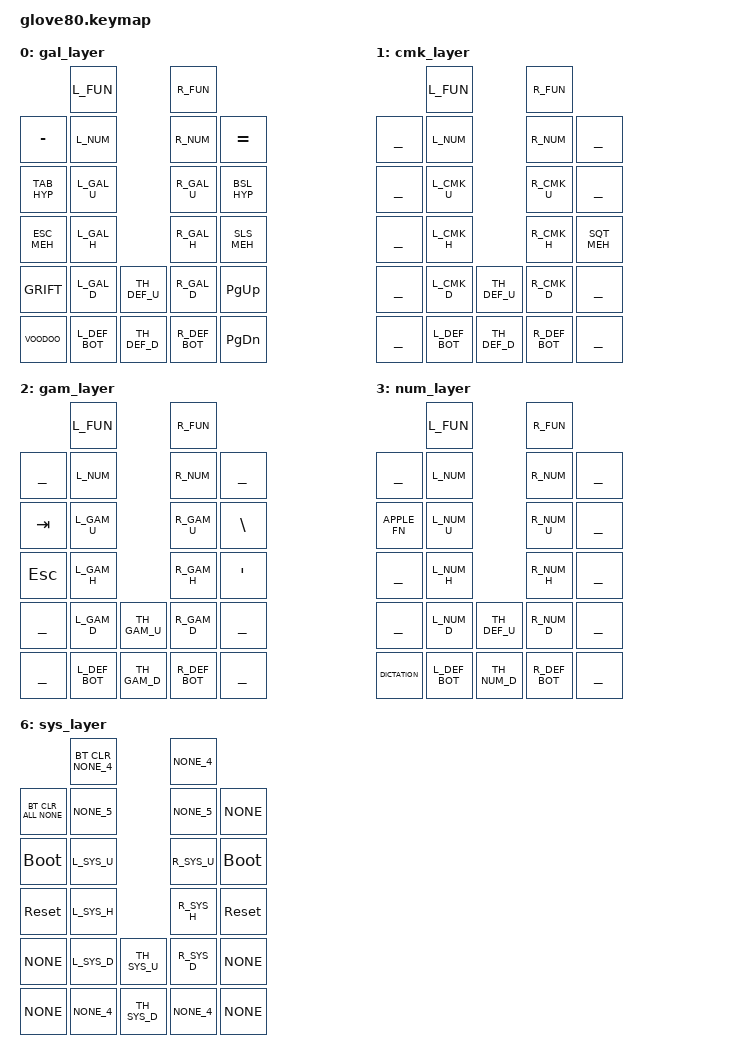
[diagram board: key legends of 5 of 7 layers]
#include <behaviors.dtsi>
#include <dt-bindings/zmk/keys.h>
#include <dt-bindings/zmk/bt.h>
#include <dt-bindings/zmk/ext_power.h>
#include <dt-bindings/zmk/outputs.h>
#include <dt-bindings/zmk/rgb.h>
#include <dt-bindings/zmk/mouse.h>

#include "../zmk-nodefree-config/helper.h"
#include "../zmk-nodefree-config/keypos_def/keypos_glv80.h"

#include "defines.h"
#include "keypos_groups_glv80.h"
#include "custom_behaviors.dtsi"
#include "behaviors_glv80.dtsi"
#include "key_codes.h"
#include "mouse.dtsi"
#include "key_clusters.h"
#include "combos.dtsi"

/* 👍 Thumb Clusters */

// Default 
//               LEFT                          <|>                 RIGHT
#define TH_DEF_U ___      ___        ___         ___      ___      PTR_ENT 
#define TH_DEF_D SPC_NUM  CMD_TAB    OPT_ESC     PTR_ENT  NAV_KEY  SFT_BSP 

#define TH_GAM_U &kp LSHFT &kp DEL   &kp LGUI    ___       ___     ___ 
#define TH_GAM_D &kp SPC   &kp LCTRL &kp LALT    PTR_ENT  NAV_KEY  SFT_BSP 

#define TH_SYS_U &bt_2     &bt_3     ___           NONE_3
#define TH_SYS_D &bt_0     &bt_1     &out OUT_USB  NONE_3

#define TH_NUM_D ___       ___       ___         NONE     &kp DOT  ___ 
#define TH_NAV_D &kp SPACE &kp TAB   &kp ESC     NONE     ___      DICTATION
#define TH_PTR_D &kp SPACE &kp TAB   &kp ESC     U_MS_B3  U_MS_B1  U_MS_B2 

ZMK_LAYER(gal_layer, 
               L_FUN              R_FUN
    &kp MINUS  L_NUM              R_NUM      &kp EQUAL
    TAB_HYP    L_GAL_U            R_GAL_U    BSL_HYP
    ESC_MEH    L_GAL_H            R_GAL_H    SLS_MEH
    GRIFT      L_GAL_D   TH_DEF_U R_GAL_D    &kp PG_UP
    VOODOO     L_DEF_BOT TH_DEF_D R_DEF_BOT  &kp PG_DN    
)

ZMK_LAYER(cmk_layer, 
               L_FUN              R_FUN
    ___        L_NUM              R_NUM      ___
    ___        L_CMK_U            R_CMK_U    ___
    ___        L_CMK_H            R_CMK_H    SQT_MEH
    ___        L_CMK_D   TH_DEF_U R_CMK_D    ___
    ___        L_DEF_BOT TH_DEF_D R_DEF_BOT  ___
)

ZMK_LAYER(gam_layer, 
               L_FUN              R_FUN
    ___        L_NUM              R_NUM      ___
    &kp TAB    L_GAM_U            R_GAM_U    &kp BACKSLASH
    &kp ESC    L_GAM_H            R_GAM_H    &kp SQT
    ___        L_GAM_D   TH_GAM_U R_GAM_D    ___
    ___        L_DEF_BOT TH_GAM_D R_DEF_BOT  ___
)

ZMK_LAYER(num_layer, 
              L_FUN              R_FUN
    ___       L_NUM              R_NUM      ___
    APPLE_FN  L_NUM_U            R_NUM_U    ___
    ___       L_NUM_H            R_NUM_H    ___
    ___       L_NUM_D   TH_DEF_U R_NUM_D    ___
    DICTATION L_DEF_BOT TH_NUM_D R_DEF_BOT  ___
)

ZMK_LAYER(nav_layer, 
    &kp F11 &kp F12  TRAN_3 TRAN_3   &kp C_BRI_DN &kp C_BRI_UP
    ___  L_NUM              R_NUM      ___
    ___  L_NAV_U            R_NAV_U    ___
    ___  L_NAV_H            R_NAV_H    ___
    ___  L_NAV_D   TH_DEF_U R_NAV_D    ___
    ___  L_DEF_BOT TH_NAV_D R_DEF_BOT  ___   
)

ZMK_LAYER(ptr_layer, 
                           // CHANGE BASE KEYMAP LAYER on F6-F10
         L_FUN        TO_GAL TO_CMK TO_GAM EXIT EXIT
    ___  L_NUM              R_NUM      ___
    ___  L_PTR_U            R_PTR_U    ___
    ___  L_PTR_H            R_PTR_H    ___
    ___  L_PTR_D   TH_DEF_U R_PTR_D    ___
    ___  L_DEF_BOT TH_PTR_D R_DEF_BOT  ___
)

ZMK_LAYER(sys_layer, 
    &bt BT_CLR  NONE_4             NONE_4 &bt BT_CLR_ALL
    NONE        NONE_5             NONE_5 NONE
    &bootloader L_SYS_U           R_SYS_U &bootloader
    &sys_reset  L_SYS_H           R_SYS_H &sys_reset
    NONE        L_SYS_D  TH_SYS_U R_SYS_D NONE
    NONE        NONE_4   TH_SYS_D NONE_4  NONE
)

// ZMK_LAYER(rec_layer, 
//          L_FUN                 R_FUN
//     ___  L_NUM                 R_NUM    ___
//     ___  L_REC_U               R_REC_U  ___
//     ___  L_REC_H               R_REC_H  ___
//     ___  L_REC_D TRAN_3 TRAN_3 R_REC_D  ___
//     ___  TRAN_4  TRAN_3 TRAN_3 TRAN_4   ___
// )

// ZMK_LAYER(fun_layer, 
//          L_FUN                 R_FUN
//     ___  L_FUN                 R_FUN    ___
//     ___  L_FUN_U               R_FUN_U  ___
//     ___  L_FUN_H               R_FUN_H  ___
//     ___  L_FUN_D TRAN_3 TRAN_3 R_FUN_D  ___
//     ___  TRAN_4  TRAN_3 TRAN_3 TRAN_4   ___
// )

// ZMK_LAYER(mod_layer, 
//          NONE_5                NONE_5 
//     ___  NONE_5                NONE_5  ___
//     ___  L_MOD_U               R_MOD_U ___
//     ___  L_MOD_H               R_MOD_H ___
//     ___  L_MOD_D NONE_3 NONE_3 R_MOD_D ___
//     ___  NONE_4  NONE_3 NONE_3 NONE_4  ___
// )

/* none 
    NONE_5               NONE_5 
___ NONE_5               NONE_5 ___
___ NONE_5               NONE_5 ___
___ NONE_5               NONE_5 ___
___ NONE_5 NONE_3 NONE_3 NONE_5 ___
___ NONE_4 NONE_3 NONE_3 NONE_4 ___
*/
